# ddr32ss_EMIF_SSCFG_0F300000h register map
Vendor: Texas Instruments
Peripheral module from a debugger description file (folder am62D).
Registers are 32-bit, read-write, reset 0x0 unless marked. A register's access mark holds for its fields unless they carry their own. Offsets are as the file gives them; lines under a group give offsets from that group; [hi:lo] are bit positions; {n}, {i} and the like mark numbered series; 'fields as' and 'values as' point back to an identical list; <NAME> marks a mode.

## emif_sscfg
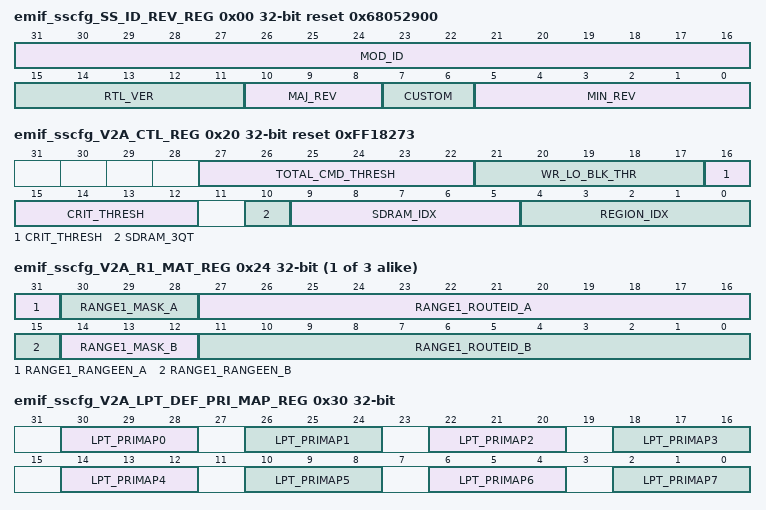
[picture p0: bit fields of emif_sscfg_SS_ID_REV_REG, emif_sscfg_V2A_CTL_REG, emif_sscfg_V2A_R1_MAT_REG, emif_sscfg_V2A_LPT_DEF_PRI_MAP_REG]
0x00 emif_sscfg_SS_ID_REV_REG ro reset 0x68052900 — The Subsystem ID and Revision Register contains the module ID, major, and minor revisions for the subsystem.
  [31:16] MOD_ID — Module ID Reset Source: ctl_smod_g_rst_n
  [15:11] RTL_VER — RTL version Reset Source: ctl_smod_g_rst_n
  [10:8] MAJ_REV — Major revision Reset Source: ctl_smod_g_rst_n
  [7:6] CUSTOM — Custom Reset Source: ctl_smod_g_rst_n
  [5:0] MIN_REV — Minor revision Reset Source: ctl_smod_g_rst_n
0x04 emif_sscfg_SS_CTL_REG — The Subsystem Control Register contains fields for control functions required for submodules in the subsystem.
  [0] PHY_PLL_BYPASS — Cadence PHY De-Skew PLL bypass. Write 1 to bypass PLL. Reset Source: ctl_smod_g_rst_n
0x20 emif_sscfg_V2A_CTL_REG reset 0xFF18273 — The VBUSM2AXI Control register contains control functions required for the VBUSM2AXI submodule.
  [27:22] TOTAL_CMD_THRESH — Total command threshold. The VBUSM2AXI bridge will block all commands to DDR when the total number of commands sent to the Cadence controller is greater than this value. The reset value of this field is optimal; however, it can be changed for better traffic shaping. Reset Source: ctl_smod_g_rst_n
  [21:17] WR_LO_BLK_THR — Write data threshold in 32 byte quantas. The VBUSM2AXI bridge will block all Low Priority Thread writes to DDR when the total number of write data bytes sent to the Cadence controller is greater than this value. The reset value of this field is optimal; however, it can be changed for better traffic shaping. Reset Source: ctl_smod_g_rst_n
  [16:12] CRIT_THRESH — Critical threshold. The VBUSM2AXI bridge will block all Low Priority Thread traffic to DDR when the total number of commands sent to the Cadence controller is greater than this value. The reset value of this field is optimal; however, it can be changed for better traffic shaping. This value must always be programmed less than total_cmd_thresh Reset Source: ctl_smod_g_rst_n
  [10] SDRAM_3QT — Setting this field to a 1 will modify SDRAM Index to be 3/4 its programmed value to support 3, 6, 12 and 24 GB sizes. Reset Source: ctl_smod_g_rst_n
  [9:5] SDRAM_IDX — SDRAM Index = log2(connected SDRAM size) - 16. The sdram_idx describes the number of address bits minus 16 that are used to determine the mask used to detect memory rollover and prevent aliasing and false coherency issues. Max size supported is 32GB. A programmed value greater than 0x13 will result in this field being reset to 0x13. Reset Source: ctl_smod_g_rst_n
  [4:0] REGION_IDX — Region Index = log2(CBA region size) - 16. The region_idx describes the number of address bits minus 16 that are used to determine the mask used to detect memory rollover and prevent aliasing and false coherency issues. Max size supported is 32GB. A programmed value greater than 0x13 will result in this field being reset to 0x13. Reset Source: ctl_smod_g_rst_n
{0x20+4i} emif_sscfg_V2A_R{i}_MAT_REG (i=1..3) — The Range {i} Match Register allows a single master to a range of masters to change their priority mapping. This allows selective masters to be increased or decreased in effective priority. Range {i} Match Register uses the associated Range {i} Priority Map Register. The highest Range Match Register will take priority and will be used in case of multiple range matches.
  [31] RANGE{i}_RANGEEN_A — The range{i}_rangeen_a enables the RouteID AND'd with range{i}_mask_a to match the range{i}_routeid_a Reset Source: ctl_smod_g_rst_n
  [30:28] RANGE{i}_MASK_A — The range{i}_mask_a allows a number of least significant bits to be ignored prior to the match of the routeid_a Reset Source: ctl_smod_g_rst_n
  [27:16] RANGE{i}_ROUTEID_A — The range{i}_routeid_a is the value that is compared to the RouteID arriving on the command interface Reset Source: ctl_smod_g_rst_n
  [15] RANGE{i}_RANGEEN_B — The range{i}_rangeen_b enables the RouteID AND'd with range{i}_mask_b to match the range{i}_routeid_b Reset Source: ctl_smod_g_rst_n
  [14:12] RANGE{i}_MASK_B — The range{i}_mask_b allows a number of least significant bits to be ignored prior to the match of the routeid_b Reset Source: ctl_smod_g_rst_n
  [11:0] RANGE{i}_ROUTEID_B — The range{i}_routeid_b is the value that is compared to the RouteID arriving on the command interface Reset Source: ctl_smod_g_rst_n
0x30 emif_sscfg_V2A_LPT_DEF_PRI_MAP_REG — The LPT Default Priority Mapping Register is the default map for the inbound VBUSM priority on the Low Priority Thread to the AXI priority.
  [30-4n:28-4n] LPT_PRIMAP{n} (n=0..7) — The field contains AXI priority value for VBUSM priority {n}. 0=highest priority. 7=lowest priority Reset Source: ctl_smod_g_rst_n
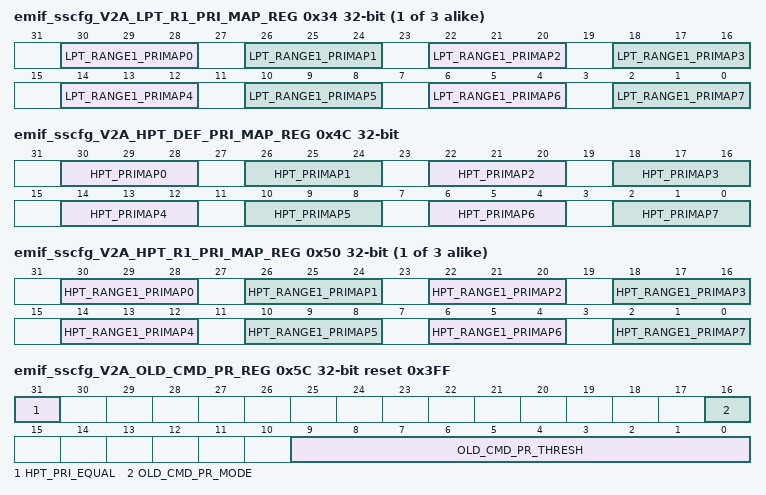
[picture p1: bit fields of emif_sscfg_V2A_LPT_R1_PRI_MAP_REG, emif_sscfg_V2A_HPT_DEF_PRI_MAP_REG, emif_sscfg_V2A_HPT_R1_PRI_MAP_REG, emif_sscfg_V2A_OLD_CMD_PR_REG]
{0x30+4i} emif_sscfg_V2A_LPT_R{i}_PRI_MAP_REG (i=1..3) — The LPT Range {i} Priority Mapping Register is used to map the inbound VBUSM priority on the Low Priority Thread to AXI priority when a RouteID match {i} occurs. This allows the priority level to be changed from the LPT Default Priority Mapping value.
  [30-4n:28-4n] LPT_RANGE{i}_PRIMAP{n} (n=0..7) — The field contains AXI priority value for VBUSM priority {n} for range match {i}. 0=highest priority. 7=lowest priority Reset Source: ctl_smod_g_rst_n
0x4C emif_sscfg_V2A_HPT_DEF_PRI_MAP_REG — The HPT Default Priority Mapping Register is the default map for the inbound VBUSM priority on the High Priority Thread to the AXI priority.
  [30-4n:28-4n] HPT_PRIMAP{n} (n=0..7) — The field contains AXI priority value for VBUSM priority {n}. 0=highest priority. 7=lowest priority Reset Source: ctl_smod_g_rst_n
{0x4C+4i} emif_sscfg_V2A_HPT_R{i}_PRI_MAP_REG (i=1..3) — The HPT Range {i} Priority Mapping Register is used to map the inbound VBUSM priority on the High Priority Thread to AXI priority when a RouteID match {i} occurs. This allows the priority level to be changed from the HPT Default Priority Mapping value.
  [30-4n:28-4n] HPT_RANGE{i}_PRIMAP{n} (n=0..7) — The field contains AXI priority value for VBUSM priority {n} for range match {i}. 0=highest priority. 7=lowest priority Reset Source: ctl_smod_g_rst_n
0x5C emif_sscfg_V2A_OLD_CMD_PR_REG reset 0x3FF
  [31] HPT_PRI_EQUAL — Setting to 1 will disable priority-based arbitration among the HPT commands. Reset Source: ctl_smod_g_rst_n
  [16] OLD_CMD_PR_MODE — Oldest Command Priority Raise mode. Setting to 0 will count LPT commands sent while oldest command is waiting. Setting to 1 will count all commands sent while oldest command is waiting. Reset Source: ctl_smod_g_rst_n
  [9:0] OLD_CMD_PR_THRESH — Oldest Command Priority Raise threshold. Number of commands sent in a row before the oldest command in the command FIFO is forwarded. This value must always be programmed greater than leaky thresholds. Reset Source: ctl_smod_g_rst_n
0x68 emif_sscfg_V2A_LEAKY_THRESH_REG reset 0xFF
  [7:0] SYS_LEAKY_THRESH — System Leaky Bucket threshold. Number of HPT commands sent in a row before a single LPT command is forwarded. A programmed value less than 0x4 will result in this field being reset to 0xFF. Reset Source: ctl_smod_g_rst_n
0x6C emif_sscfg_V2A_DRAIN_THRESH_REG reset 0x3FF
  [9:0] SYS_DRAIN_THRESH — System Drain threshold. Number of commands sent to the Cadence controller after which controller drain will be enabled. A programmed value less than 0x020 will result in this field being reset to 0x3FF. Reset Source: ctl_smod_g_rst_n
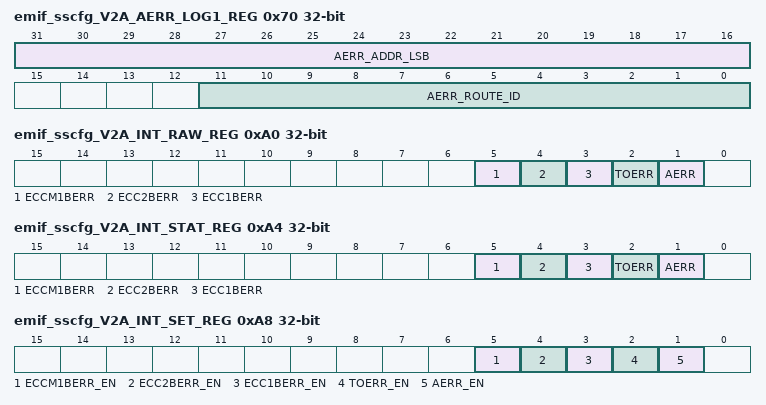
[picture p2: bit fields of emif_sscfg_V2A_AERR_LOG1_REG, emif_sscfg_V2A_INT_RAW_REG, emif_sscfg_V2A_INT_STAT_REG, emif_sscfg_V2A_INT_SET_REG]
0x70 emif_sscfg_V2A_AERR_LOG1_REG access not given — The Address Error Log 1 register displays the RouteID and lsb of the address for the first VBUSM command that was outside the programmed addressing range. Writing a 0x1 will clear all fields. Writing any other value has no effect. The Address Error Log 2 register will also be cleared upon writing this register.
  [31:16] AERR_ADDR_LSB — Address[15:0] of the VBUSM command Reset Source: ctl_smod_g_rst_n (access R/W1TC)
  [11:0] AERR_ROUTE_ID — RouteID of the VBUSM write command Reset Source: ctl_smod_g_rst_n (access R/W1TC)
0x74 emif_sscfg_V2A_AERR_LOG2_REG ro — The Address Error Log 2 registers displays the msb of the address for the first VBUSM command that was outside the programmed addressing range. This register will be cleared upon writing the Address Error Log 1 register.
  [31:0] AERR_ADDR_MSB — Address[34:16] of the VBUSM command Reset Source: ctl_smod_g_rst_n
0x9C emif_sscfg_V2A_BUS_TO reset 0xFFFFFF
  [23:0] BUS_TIMER — AXI bus timeout value. Number of DDR clock cycles after which the VBUSM2AXI bridge times out if a hang on the controller AXI interface is detected. A value of N will be equal to N x 16 clocks. Writing a 0 will disable the timeout feature. Reset Source: ctl_smod_g_rst_n
0xA0 emif_sscfg_V2A_INT_RAW_REG access not given
  [5] ECCM1BERR — Raw status of SDRAM ECC multi 1-bit errors in same SDRAM burst. Write 1 to set the (raw) status, mostly for debug. Writing a 0 has no effect. Reset Source: ctl_smod_g_rst_n (access R/W1TS)
  [4] ECC2BERR — Raw status of SDRAM ECC 2-bit error. Write 1 to set the (raw) status, mostly for debug. Writing a 0 has no effect. Reset Source: ctl_smod_g_rst_n (access R/W1TS)
  [3] ECC1BERR — Raw status of SDRAM ECC 1-bit error. Write 1 to set the (raw) status, mostly for debug. Writing a 0 has no effect. Reset Source: ctl_smod_g_rst_n (access R/W1TS)
  [2] TOERR — Raw status of VBUSM2AXI interrupt for controller AXI interface timeout. Write 1 to set the (raw) status, mostly for debug. Writing a 0 has no effect. Reset Source: ctl_smod_g_rst_n (access R/W1TS)
  [1] AERR — Raw status of VBUSM2AXI interrupt for VBUSM address outside the programmed range. Write 1 to set the (raw) status, mostly for debug. Writing a 0 has no effect. Reset Source: ctl_smod_g_rst_n (access R/W1TS)
0xA4 emif_sscfg_V2A_INT_STAT_REG access not given
  [5] ECCM1BERR — Enabled status of SDRAM ECC multi 1-bit errors in same SDRAM burst. Write 1 to clear the status after interrupt has been serviced (raw status gets cleared, i.e. even if not enabled). Writing a 0 has no effect. Reset Source: ctl_smod_g_rst_n (access R/W1TC)
  [4] ECC2BERR — Enabled status of SDRAM ECC 2-bit error. Write 1 to clear the status after interrupt has been serviced (raw status gets cleared, i.e. even if not enabled). Writing a 0 has no effect. Reset Source: ctl_smod_g_rst_n (access R/W1TC)
  [3] ECC1BERR — Enabled status of SDRAM ECC 1-bit error. Write 1 to clear the status after interrupt has been serviced (raw status gets cleared, i.e. even if not enabled). Writing a 0 has no effect. Reset Source: ctl_smod_g_rst_n (access R/W1TC)
  [2] TOERR — Enabled status of VBUSM2AXI interrupt for controller AXI interface timeout. Write 1 to clear the status after interrupt has been serviced (raw status gets cleared, i.e. even if not enabled). Writing a 0 has no effect. Reset Source: ctl_smod_g_rst_n (access R/W1TC)
  [1] AERR — Enabled status of VBUSM2AXI interrupt for VBUSM address outside the programmed range. Write 1 to clear the status after interrupt has been serviced (raw status gets cleared, i.e. even if not enabled). Writing a 0 has no effect. Reset Source: ctl_smod_g_rst_n (access R/W1TC)
0xA8 emif_sscfg_V2A_INT_SET_REG access not given
  [5] ECCM1BERR_EN — Enable set for SDRAM ECC multi 1-bit errors in same SDRAM burst. Writing a 1 will enable the interrupt, and set this bit as well as the corresponding Interrupt Enable Clear Register. Writing a 0 has no effect. Reset Source: ctl_smod_g_rst_n (access R/W1TS)
  [4] ECC2BERR_EN — Enable set for SDRAM ECC 2-bit error. Writing a 1 will enable the interrupt, and set this bit as well as the corresponding Interrupt Enable Clear Register. Writing a 0 has no effect. Reset Source: ctl_smod_g_rst_n (access R/W1TS)
  [3] ECC1BERR_EN — Enable set for SDRAM ECC 1-bit error. Writing a 1 will enable the interrupt, and set this bit as well as the corresponding Interrupt Enable Clear Register. Writing a 0 has no effect. Reset Source: ctl_smod_g_rst_n (access R/W1TS)
  [2] TOERR_EN — Enable set for VBUSM2AXI interrupt for controller AXI interface timeout. Writing a 1 will enable the interrupt, and set this bit as well as the corresponding Interrupt Enable Clear Register. Writing a 0 has no effect. Reset Source: ctl_smod_g_rst_n (access R/W1TS)
  [1] AERR_EN — Enable set for VBUSM2AXI interrupt for VBUSM address outside the programmed range. Writing a 1 will enable the interrupt, and set this bit as well as the corresponding Interrupt Enable Clear Register. Writing a 0 has no effect. Reset Source: ctl_smod_g_rst_n (access R/W1TS)
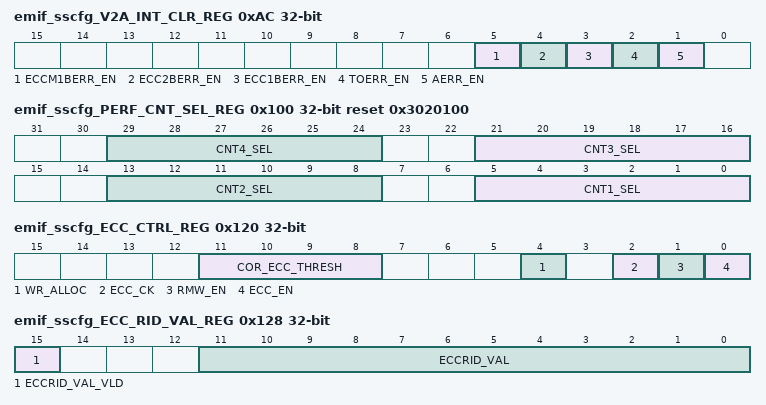
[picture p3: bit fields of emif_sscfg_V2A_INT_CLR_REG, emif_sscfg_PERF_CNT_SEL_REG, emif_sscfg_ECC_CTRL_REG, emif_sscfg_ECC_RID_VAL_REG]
0xAC emif_sscfg_V2A_INT_CLR_REG access not given
  [5] ECCM1BERR_EN — Enable clear for SDRAM ECC multi 1-bit errors in same SDRAM burst. Writing a 1 will disable the interrupt, and clear this bit as well as the corresponding Interrupt Enable Set Register. Writing a 0 has no effect. Reset Source: ctl_smod_g_rst_n (access R/W1TC)
  [4] ECC2BERR_EN — Enable clear for SDRAM ECC 2-bit error. Writing a 1 will disable the interrupt, and clear this bit as well as the corresponding Interrupt Enable Set Register. Writing a 0 has no effect. Reset Source: ctl_smod_g_rst_n (access R/W1TC)
  [3] ECC1BERR_EN — Enable clear for SDRAM ECC 1-bit error. Writing a 1 will disable the interrupt, and clear this bit as well as the corresponding Interrupt Enable Set Register. Writing a 0 has no effect. Reset Source: ctl_smod_g_rst_n (access R/W1TC)
  [2] TOERR_EN — Enable clear for VBUSM2AXI interrupt for controller AXI interface timeout. Writing a 1 will disable the interrupt, and clear this bit as well as the corresponding Interrupt Enable Set Register. Writing a 0 has no effect. Reset Source: ctl_smod_g_rst_n (access R/W1TC)
  [1] AERR_EN — Enable clear for VBUSM2AXI interrupt for VBUSM address outside the programmed range. Writing a 1 will disable the interrupt, and clear this bit as well as the corresponding Interrupt Enable Set Register. Writing a 0 has no effect. Reset Source: ctl_smod_g_rst_n (access R/W1TC)
0xB0 emif_sscfg_V2A_EOI_REG wo
  [1:0] EOI — Software End Of Interrupt (EOI) control. Write 0 for aerr/toerr interrupt. Write 1 for ecc1b interrupt. Write 2 for ecc2b interrupt. This field always reads 0 (no EOI memory). Reset Source: ctl_smod_g_rst_n
0x100 emif_sscfg_PERF_CNT_SEL_REG reset 0x3020100 — The Performance Counter Select register is used to select the statistic type to be counted in the corresponding Performance Counter register.
  [8n-3:8n-8] CNT{n}_SEL (n=1..4) — Statistic select for Performance Counter {n} register. 0x0 = Counts every Write command. 0x1 = Counts every Read command. 0x2 = Counts every read as a result of a RMW command. 0x3 = Counts every Activate command. 0x4 = Counts every Precharge command. 0x5 = Counts every Precharge All command. 0x6 = Counts every Mode Register Read command. 0x7 = Counts every Mode Register Write command. 0x8 = Counts every Per Bank Refresh command. 0x9 = Counts every Auto Refresh command. 0xA = Counts every ZQ Calib Long command. 0xB = Counts every ZQ Calib Short command. 0xC = Counts every Write-to-Read and Read-to-Write bus-turn-around. 0xD = Counts every Write-to-Write address collision. 0xE = Counts every Write-to-Read address collision. 0xF = Counts every Read-to-Write address collision. 0x10 = Counts every Read-to-Read address collision. 0x11 = Counts every exit from Power-Down Self-Refresh mode. 0x12 = Counts every entry into Power-Down Self-Refresh mode. 0x13 = Counts every cycle for which the DDR Controller stays in Power-Down Self-Refresh mode. 0x14 = Counts every exit from Power-Down mode. 0x15 = Counts every entry into Power-Down mode. 0x16 = Counts every cycle for which the DDR Controller stays in Power-Down mode. 0x17 = Counts every exit from Self-Refresh mode. 0x18 = Counts every entry into Self-Refresh mode. 0x19 = Counts every cycle for which the DDR Controller stays in Self-Refresh mode. 0x1A = Reserved 0x1B = Reserved 0x1C = Counts every cycle for which the DDR Controller command queue is full. 0x1D = Counts every cycle for which the DDR Controller info FIFO is full. 0x1E = Counts every cycle for which the DDR Controller write latency FIFO is full. 0x1F = Counts every cycle for which the DDR Controller port command FIFO is full. 0x20 = Counts every cycle for which the DDR Controller write response FIFO is full. 0x21 = Counts every cycle for which the DDR Controller port write FIFO is full. 0x22 = Counts every cycle for which the DDR Controller core read FIFO is full. 0x23 = Counts every cycle for which the DDR Controller port read FIFO is full. 0x24-0x2F = Reserved Reset Source: ctl_smod_g_rst_n
{0x100+4i} emif_sscfg_PERF_CNT{i}_REG ro (i=1..4)
  [31:0] CNT{i} — Soft 32-bit counter that can be configured as specified in the Performance Counter Select Register. Reset Source: ctl_smod_g_rst_n
0x120 emif_sscfg_ECC_CTRL_REG
  [11:8] COR_ECC_THRESH — Threshold for 1-bit ECC errors in multiple data words in an SDRAM burst that create an uncorrected error fault indication. Value of 0/1 means 2 or more 1-bit errors in multiple data words will result in an uncorrected error fault indication, value of 2 means 3 or more 1-bit errors will result in an uncorrected error fault indication, and so on. Value of 8 or greater disables this feature. This field must always be kept at default, and only changed for debug. Reset Source: ctl_smod_g_rst_n
  [4] WR_ALLOC — When set to 1, an unassigned ECC cache-line will be allocated for a write with routeID that do not match any of the mapped routeID's. Reset Source: ctl_smod_g_rst_n
  [2] ECC_CK — Set 1 to enable ECC verification for read accesses when ecc_en=1. The value of this field is ignored when ecc_en=0. This bit must be set and kept static before using DDR. Reset Source: ctl_smod_g_rst_n
  [1] RMW_EN — Read modify write enable. Set 1 to enable RMW functionality for sub-quanta accesses when ecc_en=1. This bit must be set to 1 if ecc_en is set to a 1 to ensure subquanta accesses to DRAM do not result in ECC errors. This bit must be set and kept static before using DDR. Reset Source: ctl_smod_g_rst_n
  [0] ECC_EN — DRAM ECC enable. Setting a 1 causes ECC to be written to DRAM. This bit must be set and kept static before using DDR. Reset Source: ctl_smod_g_rst_n
0x124 emif_sscfg_ECC_RID_INDX_REG
  [5:0] ECCRID_ADR — This index specifies the ECC cache entry number that the eccrid_val is mapped to. Reset Source: ctl_smod_g_rst_n
0x128 emif_sscfg_ECC_RID_VAL_REG
  [15] ECCRID_VAL_VLD — A 1 in this field indicates that value in eccrid_val is valid. Reset Source: ctl_smod_g_rst_n
  [11:0] ECCRID_VAL — RouteID value written or read. Reset Source: ctl_smod_g_rst_n
{0x130+8i} emif_sscfg_ECC_R{i}_STR_ADDR_REG reset 0xFFFF (i=0..2)
  [18:0] ECC_STR_ADR_{i} — Start caddress[34:16] for ECC range {i}. Setting the start address greater than the end address disables the range. The range is inclusive of the start and end addresses. This field must be set and kept static before using DDR. Reset Source: ctl_smod_g_rst_n
{0x134+8i} emif_sscfg_ECC_R{i}_END_ADDR_REG (i=0..2)
  [18:0] ECC_END_ADR_{i} — End caddress[34:16] for ECC range {i}. Setting the start address greater than the end address disables the range. The range is inclusive of the start and end addresses. This field must be set and kept static before using DDR. Reset Source: ctl_smod_g_rst_n
0x150 emif_sscfg_ECC_1B_ERR_CNT_REG access not given
  [15:0] ECC_1B_ERR_CNT — 16-bit counter that displays number of 1-bit ECC errors on SDRAM data. Writing a 0x1 will clear this count. Writing any other value has no effect. Reset Source: ctl_smod_g_rst_n (access R/W1TC)
0x154 emif_sscfg_ECC_1B_ERR_THRSH_REG
  [15:0] ECC_1B_ERR_THRSH — ECC 1-bit error threshold. The bridge will generate an interrupt when the ECC 1-bit error count is equal to or greater than this threshold. A value of 0 will disable the generation of interrupt. Reset Source: ctl_smod_g_rst_n
0x158 emif_sscfg_ECC_1B_ERR_ADR_LOG_REG access not given
  [30:0] ECC_1B_ERR_ADR — ECC 1-bit error address. 32-byte aligned address that had the 1-bit ECC error. This field displays the first address logged in the 2 deep logging FIFO. Writing a 0x1 will pop the top element of the FIFO. Writing any other value has no effect. Reset Source: ctl_smod_g_rst_n (access R/W1TC)
0x15C emif_sscfg_ECC_1B_ERR_MSK_LOG_REG ro
  [7:0] ECC_1B_ERR_MSK — ECC 1-bit error mask. Mask for the 64-byte data block that had the 1-bit ECC errors. Each bit represents an ECC quanta (8 bytes) in the 64-byte data block starting at address specified by ecc_1b_err_adr. Value of 1 on the bit represents an error in that particular 8 bytes. This field displays the first mask logged in the 2 deep logging FIFO along with the ecc_1b_err_adr. The same mechanism used to pop ecc_1b_err_adr is used to pop this field. Reset Source: ctl_smod_g_rst_n
0x160 emif_sscfg_ECC_2B_ERR_ADR_LOG_REG access not given
  [30:0] ECC_2B_ERR_ADR — ECC 2-bit error address. 32-byte aligned address that had the 2-bit ECC error. Writing a 0x1 will clear this field and the ecc_2b_err_msk field. Writing any other value has no effect. Reset Source: ctl_smod_g_rst_n (access R/W1TC)
0x164 emif_sscfg_ECC_2B_ERR_MSK_LOG_REG ro
  [7:0] ECC_2B_ERR_MSK — ECC 2-bit error mask. Mask for the 64-byte data block that had the 2-bit ECC errors. Each bit represents an ECC quanta (8 bytes) in the 64-byte data block starting at address specified by ecc_2b_err_adr. Value of 1 on the bit represents an error in that particular 8 bytes. Reset Source: ctl_smod_g_rst_n
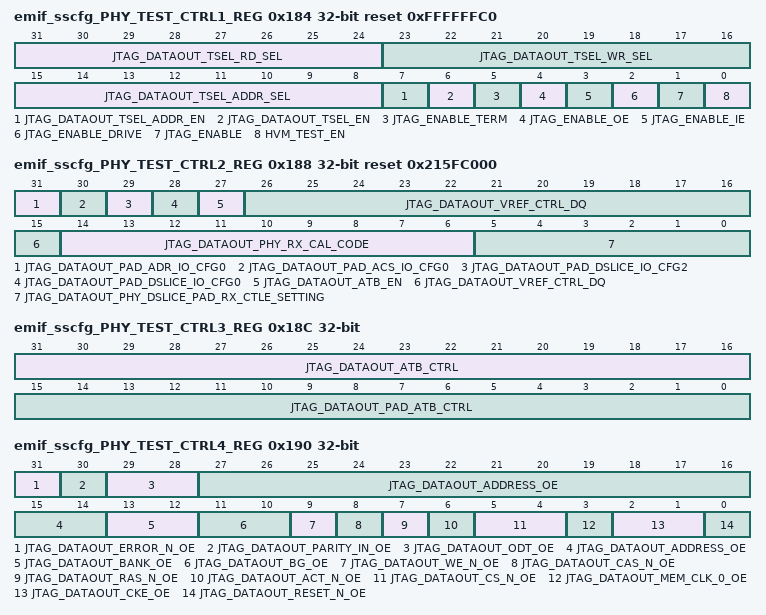
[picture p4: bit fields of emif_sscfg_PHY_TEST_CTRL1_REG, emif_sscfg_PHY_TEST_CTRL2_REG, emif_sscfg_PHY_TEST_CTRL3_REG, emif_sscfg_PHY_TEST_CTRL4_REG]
0x184 emif_sscfg_PHY_TEST_CTRL1_REG reset 0xFFFFFFC0
  [31:24] JTAG_DATAOUT_TSEL_RD_SEL — Controls jtag_dataout_tsel_rd_sel port on the PHY when ddrss_bs_mode=0 and hvm_test_en=1. Reset Source: ctl_smod_g_rst_n
  [23:16] JTAG_DATAOUT_TSEL_WR_SEL — Controls jtag_dataout_tsel_wr_sel port on the PHY when ddrss_bs_mode=0 and hvm_test_en=1. Reset Source: ctl_smod_g_rst_n
  [15:8] JTAG_DATAOUT_TSEL_ADDR_SEL — Controls jtag_dataout_tsel_addr_sel port on the PHY when ddrss_bs_mode=0 and hvm_test_en=1. Reset Source: ctl_smod_g_rst_n
  [7] JTAG_DATAOUT_TSEL_ADDR_EN — Controls jtag_dataout_tsel_addr_en port on the PHY when ddrss_bs_mode=0 and hvm_test_en=1. Reset Source: ctl_smod_g_rst_n
  [6] JTAG_DATAOUT_TSEL_EN — Controls jtag_dataout_tsel_en port on the PHY when ddrss_bs_mode=0 and hvm_test_en=1. Reset Source: ctl_smod_g_rst_n
  [5] JTAG_ENABLE_TERM — Controls jtag_enable_term port on the PHY when ddrss_bs_mode=0 and hvm_test_en=1. Reset Source: ctl_smod_g_rst_n
  [4] JTAG_ENABLE_OE — Controls jtag_enable_oe port on the PHY when ddrss_bs_mode=0 and hvm_test_en=1. Reset Source: ctl_smod_g_rst_n
  [3] JTAG_ENABLE_IE — Controls jtag_enable_ie port on the PHY when ddrss_bs_mode=0 and hvm_test_en=1. Reset Source: ctl_smod_g_rst_n
  [2] JTAG_ENABLE_DRIVE — Controls jtag_enable_drive port on the PHY when ddrss_bs_mode=0 and hvm_test_en=1. Reset Source: ctl_smod_g_rst_n
  [1] JTAG_ENABLE — Controls jtag_enable port on the PHY when ddrss_bs_mode=0 and hvm_test_en=1. Reset Source: ctl_smod_g_rst_n
  [0] HVM_TEST_EN — 1=Enable HVM test functionality. 0=Disable HVM test functionality. Setting a 1 will enable control of PHY ports using PHY Test Control registers, and will enable 50 MHz clock to the jtag_dataout_pad_dslice_io_cfg[1], jtag_dataout_pad_acs_io_cfg[1], and jtag_dataout_pad_adr_io_cfg[1] ports on the PHY. Reset Source: ctl_smod_g_rst_n
0x188 emif_sscfg_PHY_TEST_CTRL2_REG reset 0x215FC000
  [31] JTAG_DATAOUT_PAD_ADR_IO_CFG0 — Controls jtag_dataout_pad_adr_io_cfg[0] port on the PHY when ddrss_bs_mode=0 and hvm_test_en=1. Reset Source: ctl_smod_g_rst_n
  [30] JTAG_DATAOUT_PAD_ACS_IO_CFG0 — Controls jtag_dataout_pad_acs_io_cfg[0] port on the PHY when ddrss_bs_mode=0 and hvm_test_en=1. Reset Source: ctl_smod_g_rst_n
  [29] JTAG_DATAOUT_PAD_DSLICE_IO_CFG2 — Controls jtag_dataout_pad_dslice_io_cfg[2] port on the PHY when ddrss_bs_mode=0 and hvm_test_en=1. Reset Source: ctl_smod_g_rst_n
  [28] JTAG_DATAOUT_PAD_DSLICE_IO_CFG0 — Controls jtag_dataout_pad_dslice_io_cfg[0] port on the PHY when ddrss_bs_mode=0 and hvm_test_en=1. Reset Source: ctl_smod_g_rst_n
  [27] JTAG_DATAOUT_ATB_EN — Controls jtag_dataout_atb_en port on the PHY when ddrss_bs_mode=0 and hvm_test_en=1. Reset Source: ctl_smod_g_rst_n
  [26:15] JTAG_DATAOUT_VREF_CTRL_DQ — Controls jtag_dataout_vref_ctrl_dq port on the PHY when ddrss_bs_mode=0 and hvm_test_en=1. Reset Source: ctl_smod_g_rst_n
  [14:6] JTAG_DATAOUT_PHY_RX_CAL_CODE — Controls jtag_dataout_phy_rx_cal_code port on the PHY when ddrss_bs_mode=0 and hvm_test_en=1. Reset Source: ctl_smod_g_rst_n
  [5:0] JTAG_DATAOUT_PHY_DSLICE_PAD_RX_CTLE_SETTING — Controls jtag_dataout_phy_dslice_pad_rx_ctle_setting port on the PHY when ddrss_bs_mode=0 and hvm_test_en=1. Reset Source: ctl_smod_g_rst_n
0x18C emif_sscfg_PHY_TEST_CTRL3_REG
  [31:16] JTAG_DATAOUT_ATB_CTRL — Controls jtag_dataout_atb_ctrl port on the PHY when ddrss_bs_mode=0 and hvm_test_en=1. Reset Source: ctl_smod_g_rst_n
  [15:0] JTAG_DATAOUT_PAD_ATB_CTRL — Controls jtag_dataout_pad_atb_ctrl port on the PHY when ddrss_bs_mode=0 and hvm_test_en=1. Reset Source: ctl_smod_g_rst_n
0x190 emif_sscfg_PHY_TEST_CTRL4_REG
  [31] JTAG_DATAOUT_ERROR_N_OE — Controls jtag_dataout_error_n_oe port on the PHY when ddrss_bs_mode=0 and hvm_test_en=1. Reset Source: ctl_smod_g_rst_n
  [30] JTAG_DATAOUT_PARITY_IN_OE — Controls jtag_dataout_parity_in_oe port on the PHY when ddrss_bs_mode=0 and hvm_test_en=1. Reset Source: ctl_smod_g_rst_n
  [29:28] JTAG_DATAOUT_ODT_OE — Controls jtag_dataout_odt_oe port on the PHY when ddrss_bs_mode=0 and hvm_test_en=1. Reset Source: ctl_smod_g_rst_n
  [27:14] JTAG_DATAOUT_ADDRESS_OE — Controls jtag_dataout_address_oe port on the PHY when ddrss_bs_mode=0 and hvm_test_en=1. Reset Source: ctl_smod_g_rst_n
  [13:12] JTAG_DATAOUT_BANK_OE — Controls jtag_dataout_bank_oe port on the PHY when ddrss_bs_mode=0 and hvm_test_en=1. Reset Source: ctl_smod_g_rst_n
  [11:10] JTAG_DATAOUT_BG_OE — Controls jtag_dataout_bg_oe port on the PHY when ddrss_bs_mode=0 and hvm_test_en=1. Reset Source: ctl_smod_g_rst_n
  [9] JTAG_DATAOUT_WE_N_OE — Controls jtag_dataout_we_n_oe port on the PHY when ddrss_bs_mode=0 and hvm_test_en=1. Reset Source: ctl_smod_g_rst_n
  [8] JTAG_DATAOUT_CAS_N_OE — Controls jtag_dataout_cas_n_oe port on the PHY when ddrss_bs_mode=0 and hvm_test_en=1. Reset Source: ctl_smod_g_rst_n
  [7] JTAG_DATAOUT_RAS_N_OE — Controls jtag_dataout_ras_n_oe port on the PHY when ddrss_bs_mode=0 and hvm_test_en=1. Reset Source: ctl_smod_g_rst_n
  [6] JTAG_DATAOUT_ACT_N_OE — Controls jtag_dataout_act_n_oe port on the PHY when ddrss_bs_mode=0 and hvm_test_en=1. Reset Source: ctl_smod_g_rst_n
  [5:4] JTAG_DATAOUT_CS_N_OE — Controls jtag_dataout_cs_n_oe port on the PHY when ddrss_bs_mode=0 and hvm_test_en=1. Reset Source: ctl_smod_g_rst_n
  [3] JTAG_DATAOUT_MEM_CLK_0_OE — Controls jtag_dataout_mem_clk_0_oe port on the PHY when ddrss_bs_mode=0 and hvm_test_en=1. Reset Source: ctl_smod_g_rst_n
  [2:1] JTAG_DATAOUT_CKE_OE — Controls jtag_dataout_cke_oe port on the PHY when ddrss_bs_mode=0 and hvm_test_en=1. Reset Source: ctl_smod_g_rst_n
  [0] JTAG_DATAOUT_RESET_N_OE — Controls jtag_dataout_reset_n_oe port on the PHY when ddrss_bs_mode=0 and hvm_test_en=1. Reset Source: ctl_smod_g_rst_n
0x194 emif_sscfg_PHY_TEST_CTRL5_REG
  [31:0] JTAG_DATAOUT_DATA_OE — Controls jtag_dataout_data_oe port on the PHY when ddrss_bs_mode=0 and hvm_test_en=1. Reset Source: ctl_smod_g_rst_n
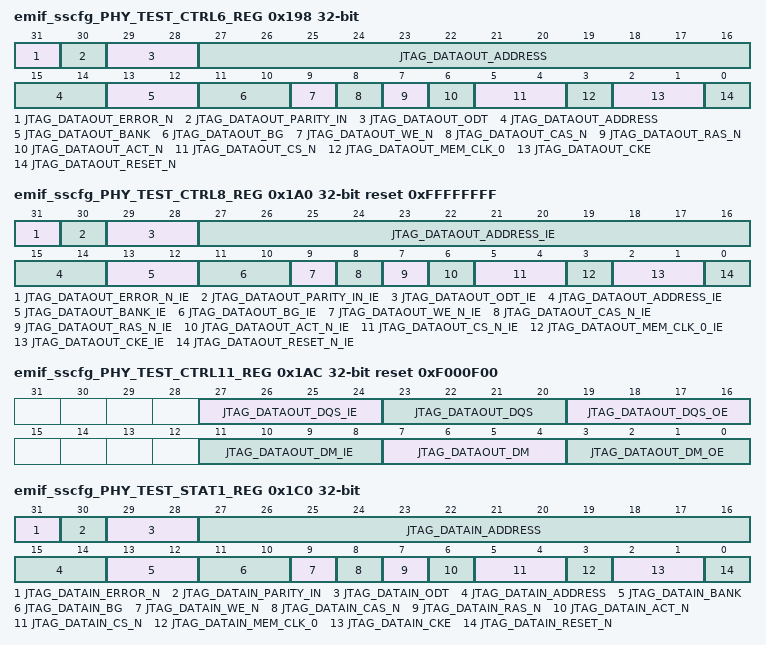
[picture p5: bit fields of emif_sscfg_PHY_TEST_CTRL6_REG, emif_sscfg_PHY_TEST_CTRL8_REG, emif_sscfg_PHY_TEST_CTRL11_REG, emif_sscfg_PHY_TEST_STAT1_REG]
0x198 emif_sscfg_PHY_TEST_CTRL6_REG
  [31] JTAG_DATAOUT_ERROR_N — Controls jtag_dataout_error_n port on the PHY when ddrss_bs_mode=0 and hvm_test_en=1. Reset Source: ctl_smod_g_rst_n
  [30] JTAG_DATAOUT_PARITY_IN — Controls jtag_dataout_parity_in port on the PHY when ddrss_bs_mode=0 and hvm_test_en=1. Reset Source: ctl_smod_g_rst_n
  [29:28] JTAG_DATAOUT_ODT — Controls jtag_dataout_odt port on the PHY when ddrss_bs_mode=0 and hvm_test_en=1. Reset Source: ctl_smod_g_rst_n
  [27:14] JTAG_DATAOUT_ADDRESS — Controls jtag_dataout_address port on the PHY when ddrss_bs_mode=0 and hvm_test_en=1. Reset Source: ctl_smod_g_rst_n
  [13:12] JTAG_DATAOUT_BANK — Controls jtag_dataout_bank port on the PHY when ddrss_bs_mode=0 and hvm_test_en=1. Reset Source: ctl_smod_g_rst_n
  [11:10] JTAG_DATAOUT_BG — Controls jtag_dataout_bg port on the PHY when ddrss_bs_mode=0 and hvm_test_en=1. Reset Source: ctl_smod_g_rst_n
  [9] JTAG_DATAOUT_WE_N — Controls jtag_dataout_we_n port on the PHY when ddrss_bs_mode=0 and hvm_test_en=1. Reset Source: ctl_smod_g_rst_n
  [8] JTAG_DATAOUT_CAS_N — Controls jtag_dataout_cas_n port on the PHY when ddrss_bs_mode=0 and hvm_test_en=1. Reset Source: ctl_smod_g_rst_n
  [7] JTAG_DATAOUT_RAS_N — Controls jtag_dataout_ras_n port on the PHY when ddrss_bs_mode=0 and hvm_test_en=1. Reset Source: ctl_smod_g_rst_n
  [6] JTAG_DATAOUT_ACT_N — Controls jtag_dataout_act_n port on the PHY when ddrss_bs_mode=0 and hvm_test_en=1. Reset Source: ctl_smod_g_rst_n
  [5:4] JTAG_DATAOUT_CS_N — Controls jtag_dataout_cs_n port on the PHY when ddrss_bs_mode=0 and hvm_test_en=1. Reset Source: ctl_smod_g_rst_n
  [3] JTAG_DATAOUT_MEM_CLK_0 — Controls jtag_dataout_mem_clk_0 port on the PHY when ddrss_bs_mode=0 and hvm_test_en=1. Reset Source: ctl_smod_g_rst_n
  [2:1] JTAG_DATAOUT_CKE — Controls jtag_dataout_cke port on the PHY when ddrss_bs_mode=0 and hvm_test_en=1. Reset Source: ctl_smod_g_rst_n
  [0] JTAG_DATAOUT_RESET_N — Controls jtag_dataout_reset_n port on the PHY when ddrss_bs_mode=0 and hvm_test_en=1. Reset Source: ctl_smod_g_rst_n
0x19C emif_sscfg_PHY_TEST_CTRL7_REG
  [31:0] JTAG_DATAOUT_DATA — Controls jtag_dataout_data port on the PHY when ddrss_bs_mode=0 and hvm_test_en=1. Reset Source: ctl_smod_g_rst_n
0x1A0 emif_sscfg_PHY_TEST_CTRL8_REG reset 0xFFFFFFFF
  [31] JTAG_DATAOUT_ERROR_N_IE — Controls jtag_dataout_error_n_ie port on the PHY when ddrss_bs_mode=0 and hvm_test_en=1. Reset Source: ctl_smod_g_rst_n
  [30] JTAG_DATAOUT_PARITY_IN_IE — Controls jtag_dataout_parity_in_ie port on the PHY when ddrss_bs_mode=0 and hvm_test_en=1. Reset Source: ctl_smod_g_rst_n
  [29:28] JTAG_DATAOUT_ODT_IE — Controls jtag_dataout_odt_ie port on the PHY when ddrss_bs_mode=0 and hvm_test_en=1. Reset Source: ctl_smod_g_rst_n
  [27:14] JTAG_DATAOUT_ADDRESS_IE — Controls jtag_dataout_address_ie port on the PHY when ddrss_bs_mode=0 and hvm_test_en=1. Reset Source: ctl_smod_g_rst_n
  [13:12] JTAG_DATAOUT_BANK_IE — Controls jtag_dataout_bank_ie port on the PHY when ddrss_bs_mode=0 and hvm_test_en=1. Reset Source: ctl_smod_g_rst_n
  [11:10] JTAG_DATAOUT_BG_IE — Controls jtag_dataout_bg_ie port on the PHY when ddrss_bs_mode=0 and hvm_test_en=1. Reset Source: ctl_smod_g_rst_n
  [9] JTAG_DATAOUT_WE_N_IE — Controls jtag_dataout_we_n_ie port on the PHY when ddrss_bs_mode=0 and hvm_test_en=1. Reset Source: ctl_smod_g_rst_n
  [8] JTAG_DATAOUT_CAS_N_IE — Controls jtag_dataout_cas_n_ie port on the PHY when ddrss_bs_mode=0 and hvm_test_en=1. Reset Source: ctl_smod_g_rst_n
  [7] JTAG_DATAOUT_RAS_N_IE — Controls jtag_dataout_ras_n_ie port on the PHY when ddrss_bs_mode=0 and hvm_test_en=1. Reset Source: ctl_smod_g_rst_n
  [6] JTAG_DATAOUT_ACT_N_IE — Controls jtag_dataout_act_n_ie port on the PHY when ddrss_bs_mode=0 and hvm_test_en=1. Reset Source: ctl_smod_g_rst_n
  [5:4] JTAG_DATAOUT_CS_N_IE — Controls jtag_dataout_cs_n_ie port on the PHY when ddrss_bs_mode=0 and hvm_test_en=1. Reset Source: ctl_smod_g_rst_n
  [3] JTAG_DATAOUT_MEM_CLK_0_IE — Controls jtag_dataout_mem_clk_0_ie port on the PHY when ddrss_bs_mode=0 and hvm_test_en=1. Reset Source: ctl_smod_g_rst_n
  [2:1] JTAG_DATAOUT_CKE_IE — Controls jtag_dataout_cke_ie port on the PHY when ddrss_bs_mode=0 and hvm_test_en=1. Reset Source: ctl_smod_g_rst_n
  [0] JTAG_DATAOUT_RESET_N_IE — Controls jtag_dataout_reset_n_ie port on the PHY when ddrss_bs_mode=0 and hvm_test_en=1. Reset Source: ctl_smod_g_rst_n
0x1A4 emif_sscfg_PHY_TEST_CTRL9_REG reset 0xFFFFFFFF
  [31:0] JTAG_DATAOUT_DATA_IE — Controls jtag_dataout_data_ie port on the PHY when ddrss_bs_mode=0 and hvm_test_en=1. Reset Source: ctl_smod_g_rst_n
0x1A8 emif_sscfg_PHY_TEST_CTRL10_REG reset 0xF
  [7:0] HVM_CLK_DIV — Divfactor to divide ddrss_ddr_pll_clk to generate PCLK for HVM tests when ddrss_bs_mode=0 and hvm_test_en=1. 0=div by 1, 1=div by 2, and so on. Reset Source: ctl_smod_g_rst_n
0x1AC emif_sscfg_PHY_TEST_CTRL11_REG reset 0xF000F00
  [27:24] JTAG_DATAOUT_DQS_IE — Controls jtag_dataout_dqs_ie port on the PHY when ddrss_bs_mode=0 and hvm_test_en=1. Reset Source: ctl_smod_g_rst_n
  [23:20] JTAG_DATAOUT_DQS — Controls jtag_dataout_dqs port on the PHY when ddrss_bs_mode=0 and hvm_test_en=1. Reset Source: ctl_smod_g_rst_n
  [19:16] JTAG_DATAOUT_DQS_OE — Controls jtag_dataout_dqs_oe port on the PHY when ddrss_bs_mode=0 and hvm_test_en=1. Reset Source: ctl_smod_g_rst_n
  [11:8] JTAG_DATAOUT_DM_IE — Controls jtag_dataout_dm_ie port on the PHY when ddrss_bs_mode=0 and hvm_test_en=1. Reset Source: ctl_smod_g_rst_n
  [7:4] JTAG_DATAOUT_DM — Controls jtag_dataout_dm port on the PHY when ddrss_bs_mode=0 and hvm_test_en=1. Reset Source: ctl_smod_g_rst_n
  [3:0] JTAG_DATAOUT_DM_OE — Controls jtag_dataout_dm_oe port on the PHY when ddrss_bs_mode=0 and hvm_test_en=1. Reset Source: ctl_smod_g_rst_n
0x1B0 emif_sscfg_PHY_TEST_CTRL12_REG
  [15:0] JTAG_DATAOUT_PHY_DSLICE_PAD_BOOSTPN_SETTING — Controls jtag_dataout_phy_dslice_pad_boostpn_setting port on the PHY when ddrss_bs_mode=0 and hvm_test_en=1. Reset Source: ctl_smod_g_rst_n
0x1C0 emif_sscfg_PHY_TEST_STAT1_REG ro
  [31] JTAG_DATAIN_ERROR_N — Displays value of jtag_datain_error_n port on the PHY. Reset Source: ctl_smod_g_rst_n
  [30] JTAG_DATAIN_PARITY_IN — Displays value of jtag_datain_parity_in port on the PHY. Reset Source: ctl_smod_g_rst_n
  [29:28] JTAG_DATAIN_ODT — Displays value of jtag_datain_odt port on the PHY. Reset Source: ctl_smod_g_rst_n
  [27:14] JTAG_DATAIN_ADDRESS — Displays value of jtag_datain_address port on the PHY. Reset Source: ctl_smod_g_rst_n
  [13:12] JTAG_DATAIN_BANK — Displays value of jtag_datain_bank port on the PHY. Reset Source: ctl_smod_g_rst_n
  [11:10] JTAG_DATAIN_BG — Displays value of jtag_datain_bg port on the PHY. Reset Source: ctl_smod_g_rst_n
  [9] JTAG_DATAIN_WE_N — Displays value of jtag_datain_we_n port on the PHY. Reset Source: ctl_smod_g_rst_n
  [8] JTAG_DATAIN_CAS_N — Displays value of jtag_datain_cas_n port on the PHY. Reset Source: ctl_smod_g_rst_n
  [7] JTAG_DATAIN_RAS_N — Displays value of jtag_datain_ras_n port on the PHY. Reset Source: ctl_smod_g_rst_n
  [6] JTAG_DATAIN_ACT_N — Displays value of jtag_datain_act_n port on the PHY. Reset Source: ctl_smod_g_rst_n
  [5:4] JTAG_DATAIN_CS_N — Displays value of jtag_datain_cs_n port on the PHY. Reset Source: ctl_smod_g_rst_n
  [3] JTAG_DATAIN_MEM_CLK_0 — Displays value of jtag_datain_mem_clk_0 port on the PHY. Reset Source: ctl_smod_g_rst_n
  [2:1] JTAG_DATAIN_CKE — Displays value of jtag_datain_cke port on the PHY. Reset Source: ctl_smod_g_rst_n
  [0] JTAG_DATAIN_RESET_N — Displays value of jtag_datain_reset_n port on the PHY. Reset Source: ctl_smod_g_rst_n
0x1C4 emif_sscfg_PHY_TEST_STAT2_REG ro
  [31:0] JTAG_DATAIN_DATA — Displays value of jtag_datain_data port on the PHY. Reset Source: ctl_smod_g_rst_n
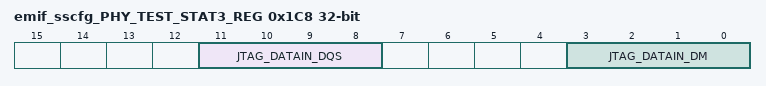
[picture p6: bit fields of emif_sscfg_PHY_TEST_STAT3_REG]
0x1C8 emif_sscfg_PHY_TEST_STAT3_REG ro
  [11:8] JTAG_DATAIN_DQS — Displays value of jtag_datain_dqs port on the PHY. Reset Source: ctl_smod_g_rst_n
  [3:0] JTAG_DATAIN_DM — Displays value of jtag_datain_dm port on the PHY. Reset Source: ctl_smod_g_rst_n
